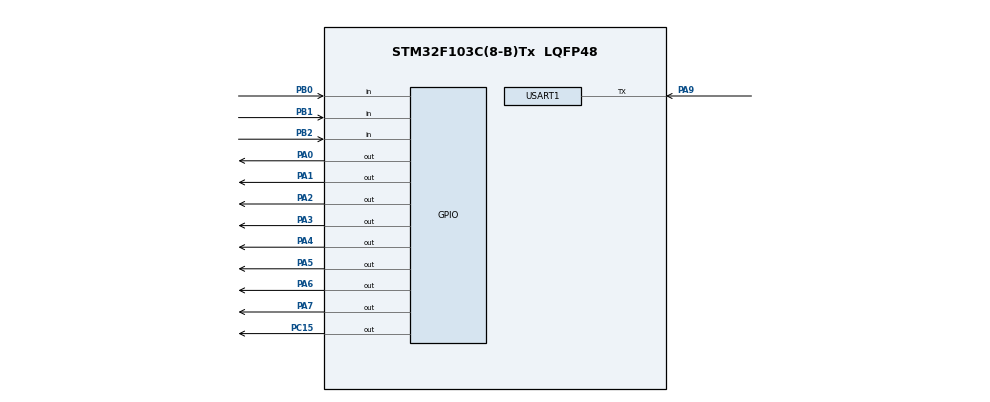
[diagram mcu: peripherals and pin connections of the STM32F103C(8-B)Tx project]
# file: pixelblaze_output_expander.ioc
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Dma.Request0=TIM1_CH1
Dma.Request1=TIM1_CH3
Dma.Request2=TIM1_CH4/TRIG/COM
Dma.Request3=USART1_RX
Dma.Request4=TIM2_CH2/CH4
Dma.TIM1_CH1.0.Direction=DMA_MEMORY_TO_PERIPH
Dma.TIM1_CH1.0.Instance=DMA1_Channel2
Dma.TIM1_CH1.0.MemDataAlignment=DMA_MDATAALIGN_BYTE
Dma.TIM1_CH1.0.MemInc=DMA_MINC_DISABLE
Dma.TIM1_CH1.0.Mode=DMA_CIRCULAR
Dma.TIM1_CH1.0.PeriphDataAlignment=DMA_PDATAALIGN_BYTE
Dma.TIM1_CH1.0.PeriphInc=DMA_PINC_DISABLE
Dma.TIM1_CH1.0.Priority=DMA_PRIORITY_VERY_HIGH
Dma.TIM1_CH3.1.Direction=DMA_MEMORY_TO_PERIPH
Dma.TIM1_CH3.1.Instance=DMA1_Channel6
Dma.TIM1_CH3.1.MemDataAlignment=DMA_MDATAALIGN_BYTE
Dma.TIM1_CH3.1.MemInc=DMA_MINC_ENABLE
Dma.TIM1_CH3.1.Mode=DMA_NORMAL
Dma.TIM1_CH3.1.PeriphDataAlignment=DMA_PDATAALIGN_BYTE
Dma.TIM1_CH3.1.PeriphInc=DMA_PINC_DISABLE
Dma.TIM1_CH3.1.Priority=DMA_PRIORITY_VERY_HIGH
Dma.TIM1_CH4/TRIG/COM.2.Direction=DMA_MEMORY_TO_PERIPH
Dma.TIM1_CH4/TRIG/COM.2.Instance=DMA1_Channel4
Dma.TIM1_CH4/TRIG/COM.2.MemDataAlignment=DMA_MDATAALIGN_BYTE
Dma.TIM1_CH4/TRIG/COM.2.MemInc=DMA_MINC_DISABLE
Dma.TIM1_CH4/TRIG/COM.2.Mode=DMA_CIRCULAR
Dma.TIM1_CH4/TRIG/COM.2.PeriphDataAlignment=DMA_PDATAALIGN_BYTE
Dma.TIM1_CH4/TRIG/COM.2.PeriphInc=DMA_PINC_DISABLE
Dma.TIM1_CH4/TRIG/COM.2.Priority=DMA_PRIORITY_VERY_HIGH
Dma.TIM2_CH2/CH4.4.Direction=DMA_MEMORY_TO_PERIPH
Dma.TIM2_CH2/CH4.4.Instance=DMA1_Channel7
Dma.TIM2_CH2/CH4.4.MemDataAlignment=DMA_MDATAALIGN_BYTE
Dma.TIM2_CH2/CH4.4.MemInc=DMA_MINC_DISABLE
Dma.TIM2_CH2/CH4.4.Mode=DMA_CIRCULAR
Dma.TIM2_CH2/CH4.4.PeriphDataAlignment=DMA_PDATAALIGN_BYTE
Dma.TIM2_CH2/CH4.4.PeriphInc=DMA_PINC_DISABLE
Dma.TIM2_CH2/CH4.4.Priority=DMA_PRIORITY_HIGH
Dma.USART1_RX.3.Direction=DMA_PERIPH_TO_MEMORY
Dma.USART1_RX.3.Instance=DMA1_Channel5
Dma.USART1_RX.3.MemDataAlignment=DMA_MDATAALIGN_BYTE
Dma.USART1_RX.3.MemInc=DMA_MINC_ENABLE
Dma.USART1_RX.3.Mode=DMA_CIRCULAR
Dma.USART1_RX.3.PeriphDataAlignment=DMA_PDATAALIGN_BYTE
Dma.USART1_RX.3.PeriphInc=DMA_PINC_DISABLE
Dma.USART1_RX.3.Priority=DMA_PRIORITY_LOW
Mcu.Family=STM32F1
Mcu.Name=STM32F103C(8-B)Tx
Mcu.Package=LQFP48
NVIC.DMA1_Channel2_IRQn=true\:0\:0\:false\:false\:true\:false\:true\:true
NVIC.DMA1_Channel4_IRQn=true\:0\:0\:false\:false\:true\:false\:true\:true
NVIC.DMA1_Channel5_IRQn=true\:0\:0\:false\:false\:true\:false\:true\:true
NVIC.DMA1_Channel6_IRQn=true\:0\:0\:false\:false\:true\:false\:true\:true
NVIC.DMA1_Channel7_IRQn=true\:0\:0\:false\:false\:true\:false\:true\:true
NVIC.PriorityGroup=NVIC_PRIORITYGROUP_4
NVIC.TIM4_IRQn=true\:0\:0\:false\:false\:true\:true\:true\:true
NVIC.USART1_IRQn=true\:0\:0\:false\:false\:true\:true\:true\:true
PA0-WKUP.Signal=GPIO_Output
PA1.Signal=GPIO_Output
PA13.Mode=Serial_Wire
PA13.Signal=SYS_JTMS-SWDIO
PA14.Mode=Serial_Wire
PA14.Signal=SYS_JTCK-SWCLK
PA2.Signal=GPIO_Output
PA3.Signal=GPIO_Output
PA4.Signal=GPIO_Output
PA5.Signal=GPIO_Output
PA6.Signal=GPIO_Output
PA7.Signal=GPIO_Output
PA9.Mode=Half_duplex(single_wire_mode)
PA9.Signal=USART1_TX
PB0.GPIO_PuPd=GPIO_PULLUP
PB0.Signal=GPIO_Input
PB1.GPIO_PuPd=GPIO_PULLUP
PB1.Signal=GPIO_Input
PB2.GPIO_PuPd=GPIO_PULLUP
PB2.Signal=GPIO_Input
PC15-OSC32_OUT.Signal=GPIO_Output
ProjectManager.HeapSize=0x0
ProjectManager.StackSize=0x0c0
ProjectManager.TargetToolchain=STM32CubeIDE
RCC.AHBFreq_Value=64000000
RCC.APB1CLKDivider=RCC_HCLK_DIV2
RCC.APB1Freq_Value=32000000
RCC.APB1TimFreq_Value=64000000
RCC.APB2Freq_Value=64000000
RCC.APB2TimFreq_Value=64000000
RCC.HCLKFreq_Value=64000000
RCC.PLLMUL=RCC_PLL_MUL16
RCC.SYSCLKFreq_VALUE=64000000
RCC.SYSCLKSource=RCC_SYSCLKSOURCE_PLLCLK
RCC.USBFreq_Value=64000000
TIM1.Channel-Output\ Compare1\ No\ Output=TIM_CHANNEL_1
TIM1.Channel-Output\ Compare3\ No\ Output=TIM_CHANNEL_3
TIM1.Channel-Output\ Compare4\ No\ Output=TIM_CHANNEL_4
TIM1.OCMode_1=TIM_OCMODE_ACTIVE
TIM1.OCMode_3=TIM_OCMODE_ACTIVE
TIM1.OCMode_4=TIM_OCMODE_ACTIVE
TIM1.Period=79
TIM1.Pulse-Output\ Compare1\ No\ Output=1
TIM1.Pulse-Output\ Compare3\ No\ Output=16
TIM1.Pulse-Output\ Compare4\ No\ Output=56
TIM2.Channel-Output\ Compare2\ No\ Output=TIM_CHANNEL_2
TIM2.OCMode_2=TIM_OCMODE_ACTIVE
TIM2.Period=79
TIM2.Pulse-Output\ Compare2\ No\ Output=64
TIM3.Channel-PWM\ Generation1\ No\ Output=TIM_CHANNEL_1
TIM3.OCMode_PWM-PWM\ Generation1\ No\ Output=TIM_OCMODE_PWM2
TIM3.Period=20159
TIM3.Prescaler=79
TIM3.Pulse-PWM\ Generation1\ No\ Output=1
TIM3.TIM_MasterOutputTrigger=TIM_TRGO_OC1REF
TIM3.TIM_MasterSlaveMode=TIM_MASTERSLAVEMODE_ENABLE
TIM4.ClockDivision=TIM_CLOCKDIVISION_DIV1
TIM4.Period=65535
TIM4.Prescaler=63
USART1.BaudRate=2000000
USART1.Mode=MODE_RX
USART1.VirtualMode=VM_ASYNC
VP_TIM1_VS_ClockSourceINT.Mode=Internal
VP_TIM1_VS_ClockSourceITR.Mode=TriggerSource_ITR2
VP_TIM1_VS_ControllerModeGated.Mode=Gated Mode
VP_TIM1_VS_no_output1.Mode=Output Compare1 No Output
VP_TIM1_VS_no_output3.Mode=Output Compare3 No Output
VP_TIM1_VS_no_output4.Mode=Output Compare4 No Output
VP_TIM2_VS_ClockSourceINT.Mode=Internal
VP_TIM2_VS_ClockSourceITR.Mode=TriggerSource_ITR2
VP_TIM2_VS_ControllerModeGated.Mode=Gated Mode
VP_TIM2_VS_no_output2.Mode=Output Compare2 No Output
VP_TIM3_VS_ClockSourceINT.Mode=Internal
VP_TIM3_VS_OPM.Mode=OPM_bit
VP_TIM3_VS_no_output1.Mode=PWM Generation1 No Output
VP_TIM4_VS_ClockSourceINT.Mode=Internal
VP_TIM4_VS_OPM.Mode=OPM_bit
board=custom

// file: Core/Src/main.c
/* USER CODE BEGIN Header */
/**
  ******************************************************************************
  * @file           : main.c
  * @brief          : Main program body
  ******************************************************************************
  * @attention
  *
  * <h2><center>&copy; Copyright (c) 2019 STMicroelectronics.
  * All rights reserved.</center></h2>
  *
  * This software component is licensed by ST under BSD 3-Clause license,
  * the "License"; You may not use this file except in compliance with the
  * License. You may obtain a copy of the License at:
  *                        opensource.org/licenses/BSD-3-Clause
  *
  ******************************************************************************
  */
/* USER CODE END Header */

#include "main.h"

/* USER CODE BEGIN Includes */

#include "app.h"

/* USER CODE END Includes */

void SystemClock_Config(void);
static void MX_GPIO_Init(void);
static void MX_USART1_UART_Init(void);
static void MX_DMA_Init(void);
static void MX_TIM1_Init(void);
static void MX_TIM3_Init(void);
static void MX_TIM4_Init(void);
static void MX_TIM2_Init(void);

int main(void)
{

  /* MCU Configuration--------------------------------------------------------*/

  /* Reset of all peripherals, Initializes the Flash interface and the Systick. */

  LL_APB2_GRP1_EnableClock(LL_APB2_GRP1_PERIPH_AFIO);
  LL_APB1_GRP1_EnableClock(LL_APB1_GRP1_PERIPH_PWR);

  NVIC_SetPriorityGrouping(NVIC_PRIORITYGROUP_4);

  /* System interrupt init*/

  /** NOJTAG: JTAG-DP Disabled and SW-DP Enabled
  */
  LL_GPIO_AF_Remap_SWJ_NOJTAG();

  /* Configure the system clock */
  SystemClock_Config();

  /* USER CODE BEGIN SysInit */

  MX_GPIO_Init();
  MX_DMA_Init(); //dma before uart, or uart dma init code fails
  MX_USART1_UART_Init();
  MX_TIM1_Init();
  MX_TIM3_Init();
  MX_TIM4_Init();
  MX_TIM2_Init();

#if 0

  /* USER CODE END SysInit */

  /* Initialize all configured peripherals */
  MX_GPIO_Init();
  MX_USART1_UART_Init();
  MX_DMA_Init();
  MX_TIM1_Init();
  MX_TIM3_Init();
  MX_TIM4_Init();
  MX_TIM2_Init();
  /* USER CODE BEGIN 2 */

#endif

  setup();

  /* USER CODE END 2 */

  /* Infinite loop */
  while (1)
  {

    /* USER CODE BEGIN 3 */
	  loop();
  }
  /* USER CODE END 3 */
}

void SystemClock_Config(void)
{
  LL_FLASH_SetLatency(LL_FLASH_LATENCY_2);

   if(LL_FLASH_GetLatency() != LL_FLASH_LATENCY_2)
  {
    Error_Handler();
  }
  LL_RCC_HSI_SetCalibTrimming(16);
  LL_RCC_HSI_Enable();

   /* Wait till HSI is ready */
  while(LL_RCC_HSI_IsReady() != 1)
  {

  }
  LL_RCC_PLL_ConfigDomain_SYS(LL_RCC_PLLSOURCE_HSI_DIV_2, LL_RCC_PLL_MUL_16);
  LL_RCC_PLL_Enable();

   /* Wait till PLL is ready */
  while(LL_RCC_PLL_IsReady() != 1)
  {

  }
  LL_RCC_SetAHBPrescaler(LL_RCC_SYSCLK_DIV_1);
  LL_RCC_SetAPB1Prescaler(LL_RCC_APB1_DIV_2);
  LL_RCC_SetAPB2Prescaler(LL_RCC_APB2_DIV_1);
  LL_RCC_SetSysClkSource(LL_RCC_SYS_CLKSOURCE_PLL);

   /* Wait till System clock is ready */
  while(LL_RCC_GetSysClkSource() != LL_RCC_SYS_CLKSOURCE_STATUS_PLL)
  {

  }
  LL_Init1msTick(64000000);
  LL_SYSTICK_SetClkSource(LL_SYSTICK_CLKSOURCE_HCLK);
  LL_SetSystemCoreClock(64000000);
}

static void MX_TIM1_Init(void)
{

  LL_TIM_InitTypeDef TIM_InitStruct = {0};
  LL_TIM_OC_InitTypeDef TIM_OC_InitStruct = {0};
  LL_TIM_BDTR_InitTypeDef TIM_BDTRInitStruct = {0};

  /* Peripheral clock enable */
  LL_APB2_GRP1_EnableClock(LL_APB2_GRP1_PERIPH_TIM1);

  /* TIM1 DMA Init */

  /* TIM1_CH1 Init */
  LL_DMA_SetDataTransferDirection(DMA1, LL_DMA_CHANNEL_2, LL_DMA_DIRECTION_MEMORY_TO_PERIPH);

  LL_DMA_SetChannelPriorityLevel(DMA1, LL_DMA_CHANNEL_2, LL_DMA_PRIORITY_VERYHIGH);

  LL_DMA_SetMode(DMA1, LL_DMA_CHANNEL_2, LL_DMA_MODE_CIRCULAR);

  LL_DMA_SetPeriphIncMode(DMA1, LL_DMA_CHANNEL_2, LL_DMA_PERIPH_NOINCREMENT);

  LL_DMA_SetMemoryIncMode(DMA1, LL_DMA_CHANNEL_2, LL_DMA_MEMORY_NOINCREMENT);

  LL_DMA_SetPeriphSize(DMA1, LL_DMA_CHANNEL_2, LL_DMA_PDATAALIGN_BYTE);

  LL_DMA_SetMemorySize(DMA1, LL_DMA_CHANNEL_2, LL_DMA_MDATAALIGN_BYTE);

  /* TIM1_CH3 Init */
  LL_DMA_SetDataTransferDirection(DMA1, LL_DMA_CHANNEL_6, LL_DMA_DIRECTION_MEMORY_TO_PERIPH);

  LL_DMA_SetChannelPriorityLevel(DMA1, LL_DMA_CHANNEL_6, LL_DMA_PRIORITY_VERYHIGH);

  LL_DMA_SetMode(DMA1, LL_DMA_CHANNEL_6, LL_DMA_MODE_NORMAL);

  LL_DMA_SetPeriphIncMode(DMA1, LL_DMA_CHANNEL_6, LL_DMA_PERIPH_NOINCREMENT);

  LL_DMA_SetMemoryIncMode(DMA1, LL_DMA_CHANNEL_6, LL_DMA_MEMORY_INCREMENT);

  LL_DMA_SetPeriphSize(DMA1, LL_DMA_CHANNEL_6, LL_DMA_PDATAALIGN_BYTE);

  LL_DMA_SetMemorySize(DMA1, LL_DMA_CHANNEL_6, LL_DMA_MDATAALIGN_BYTE);

  /* TIM1_CH4_TRIG_COM Init */
  LL_DMA_SetDataTransferDirection(DMA1, LL_DMA_CHANNEL_4, LL_DMA_DIRECTION_MEMORY_TO_PERIPH);

  LL_DMA_SetChannelPriorityLevel(DMA1, LL_DMA_CHANNEL_4, LL_DMA_PRIORITY_VERYHIGH);

  LL_DMA_SetMode(DMA1, LL_DMA_CHANNEL_4, LL_DMA_MODE_CIRCULAR);

  LL_DMA_SetPeriphIncMode(DMA1, LL_DMA_CHANNEL_4, LL_DMA_PERIPH_NOINCREMENT);

  LL_DMA_SetMemoryIncMode(DMA1, LL_DMA_CHANNEL_4, LL_DMA_MEMORY_NOINCREMENT);

  LL_DMA_SetPeriphSize(DMA1, LL_DMA_CHANNEL_4, LL_DMA_PDATAALIGN_BYTE);

  LL_DMA_SetMemorySize(DMA1, LL_DMA_CHANNEL_4, LL_DMA_MDATAALIGN_BYTE);

  TIM_InitStruct.Prescaler = 0;
  TIM_InitStruct.CounterMode = LL_TIM_COUNTERMODE_UP;
  TIM_InitStruct.Autoreload = TIM1_CYCLE_COUNT;
  TIM_InitStruct.ClockDivision = LL_TIM_CLOCKDIVISION_DIV1;
  TIM_InitStruct.RepetitionCounter = 0;
  LL_TIM_Init(TIM1, &TIM_InitStruct);
  LL_TIM_DisableARRPreload(TIM1);
  LL_TIM_SetClockSource(TIM1, LL_TIM_CLOCKSOURCE_INTERNAL);
  TIM_OC_InitStruct.OCMode = LL_TIM_OCMODE_ACTIVE;
  TIM_OC_InitStruct.OCState = LL_TIM_OCSTATE_DISABLE;
  TIM_OC_InitStruct.OCNState = LL_TIM_OCSTATE_DISABLE;
  TIM_OC_InitStruct.CompareValue = TIM1_COMPARE_CH1;
  TIM_OC_InitStruct.OCPolarity = LL_TIM_OCPOLARITY_HIGH;
  TIM_OC_InitStruct.OCNPolarity = LL_TIM_OCPOLARITY_HIGH;
  TIM_OC_InitStruct.OCIdleState = LL_TIM_OCIDLESTATE_LOW;
  TIM_OC_InitStruct.OCNIdleState = LL_TIM_OCIDLESTATE_LOW;
  LL_TIM_OC_Init(TIM1, LL_TIM_CHANNEL_CH1, &TIM_OC_InitStruct);
  LL_TIM_OC_DisableFast(TIM1, LL_TIM_CHANNEL_CH1);
  TIM_OC_InitStruct.OCState = LL_TIM_OCSTATE_DISABLE;
  TIM_OC_InitStruct.OCNState = LL_TIM_OCSTATE_DISABLE;
  TIM_OC_InitStruct.CompareValue = TIM1_COMPARE_CH3;
  LL_TIM_OC_Init(TIM1, LL_TIM_CHANNEL_CH3, &TIM_OC_InitStruct);
  LL_TIM_OC_DisableFast(TIM1, LL_TIM_CHANNEL_CH3);
  TIM_OC_InitStruct.OCState = LL_TIM_OCSTATE_DISABLE;
  TIM_OC_InitStruct.OCNState = LL_TIM_OCSTATE_DISABLE;
  TIM_OC_InitStruct.CompareValue = TIM1_COMPARE_CH4;
  LL_TIM_OC_Init(TIM1, LL_TIM_CHANNEL_CH4, &TIM_OC_InitStruct);
  LL_TIM_OC_DisableFast(TIM1, LL_TIM_CHANNEL_CH4);
  LL_TIM_SetTriggerInput(TIM1, LL_TIM_TS_ITR2);
  LL_TIM_SetSlaveMode(TIM1, LL_TIM_SLAVEMODE_GATED);
  LL_TIM_DisableIT_TRIG(TIM1);
  LL_TIM_DisableDMAReq_TRIG(TIM1);
  LL_TIM_SetTriggerOutput(TIM1, LL_TIM_TRGO_RESET);
  LL_TIM_DisableMasterSlaveMode(TIM1);
  TIM_BDTRInitStruct.OSSRState = LL_TIM_OSSR_DISABLE;
  TIM_BDTRInitStruct.OSSIState = LL_TIM_OSSI_DISABLE;
  TIM_BDTRInitStruct.LockLevel = LL_TIM_LOCKLEVEL_OFF;
  TIM_BDTRInitStruct.DeadTime = 0;
  TIM_BDTRInitStruct.BreakState = LL_TIM_BREAK_DISABLE;
  TIM_BDTRInitStruct.BreakPolarity = LL_TIM_BREAK_POLARITY_HIGH;
  TIM_BDTRInitStruct.AutomaticOutput = LL_TIM_AUTOMATICOUTPUT_DISABLE;
  LL_TIM_BDTR_Init(TIM1, &TIM_BDTRInitStruct);

}

static void MX_TIM2_Init(void)
{

  LL_TIM_InitTypeDef TIM_InitStruct = {0};
  LL_TIM_OC_InitTypeDef TIM_OC_InitStruct = {0};

  /* Peripheral clock enable */
  LL_APB1_GRP1_EnableClock(LL_APB1_GRP1_PERIPH_TIM2);

  /* TIM2 DMA Init */

  /* TIM2_CH2_CH4 Init */
  LL_DMA_SetDataTransferDirection(DMA1, LL_DMA_CHANNEL_7, LL_DMA_DIRECTION_MEMORY_TO_PERIPH);

  LL_DMA_SetChannelPriorityLevel(DMA1, LL_DMA_CHANNEL_7, LL_DMA_PRIORITY_HIGH);

  LL_DMA_SetMode(DMA1, LL_DMA_CHANNEL_7, LL_DMA_MODE_CIRCULAR);

  LL_DMA_SetPeriphIncMode(DMA1, LL_DMA_CHANNEL_7, LL_DMA_PERIPH_NOINCREMENT);

  LL_DMA_SetMemoryIncMode(DMA1, LL_DMA_CHANNEL_7, LL_DMA_MEMORY_NOINCREMENT);

  LL_DMA_SetPeriphSize(DMA1, LL_DMA_CHANNEL_7, LL_DMA_PDATAALIGN_BYTE);

  LL_DMA_SetMemorySize(DMA1, LL_DMA_CHANNEL_7, LL_DMA_MDATAALIGN_BYTE);

  TIM_InitStruct.Prescaler = 0;
  TIM_InitStruct.CounterMode = LL_TIM_COUNTERMODE_UP;
  TIM_InitStruct.Autoreload = TIM1_CYCLE_COUNT;
  TIM_InitStruct.ClockDivision = LL_TIM_CLOCKDIVISION_DIV1;
  LL_TIM_Init(TIM2, &TIM_InitStruct);
  LL_TIM_DisableARRPreload(TIM2);
  LL_TIM_SetClockSource(TIM2, LL_TIM_CLOCKSOURCE_INTERNAL);
  TIM_OC_InitStruct.OCMode = LL_TIM_OCMODE_ACTIVE;
  TIM_OC_InitStruct.OCState = LL_TIM_OCSTATE_DISABLE;
  TIM_OC_InitStruct.OCNState = LL_TIM_OCSTATE_DISABLE;
  TIM_OC_InitStruct.CompareValue = TIM2_COMPARE_CH2;
  TIM_OC_InitStruct.OCPolarity = LL_TIM_OCPOLARITY_HIGH;
  LL_TIM_OC_Init(TIM2, LL_TIM_CHANNEL_CH2, &TIM_OC_InitStruct);
  LL_TIM_OC_DisableFast(TIM2, LL_TIM_CHANNEL_CH2);
  LL_TIM_SetTriggerInput(TIM2, LL_TIM_TS_ITR2);
  LL_TIM_SetSlaveMode(TIM2, LL_TIM_SLAVEMODE_GATED);
  LL_TIM_DisableIT_TRIG(TIM2);
  LL_TIM_DisableDMAReq_TRIG(TIM2);
  LL_TIM_SetTriggerOutput(TIM2, LL_TIM_TRGO_RESET);
  LL_TIM_DisableMasterSlaveMode(TIM2);

}

static void MX_TIM3_Init(void)
{

  LL_TIM_InitTypeDef TIM_InitStruct = {0};
  LL_TIM_OC_InitTypeDef TIM_OC_InitStruct = {0};

  /* Peripheral clock enable */
  LL_APB1_GRP1_EnableClock(LL_APB1_GRP1_PERIPH_TIM3);

  TIM_InitStruct.Prescaler = TIM1_CYCLE_COUNT;
  TIM_InitStruct.CounterMode = LL_TIM_COUNTERMODE_UP;
  TIM_InitStruct.Autoreload = 20159;
  TIM_InitStruct.ClockDivision = LL_TIM_CLOCKDIVISION_DIV1;
  LL_TIM_Init(TIM3, &TIM_InitStruct);
  LL_TIM_DisableARRPreload(TIM3);
  LL_TIM_SetClockSource(TIM3, LL_TIM_CLOCKSOURCE_INTERNAL);
  LL_TIM_OC_EnablePreload(TIM3, LL_TIM_CHANNEL_CH1);
  TIM_OC_InitStruct.OCMode = LL_TIM_OCMODE_PWM2;
  TIM_OC_InitStruct.OCState = LL_TIM_OCSTATE_DISABLE;
  TIM_OC_InitStruct.OCNState = LL_TIM_OCSTATE_DISABLE;
  TIM_OC_InitStruct.CompareValue = 1;
  TIM_OC_InitStruct.OCPolarity = LL_TIM_OCPOLARITY_HIGH;
  LL_TIM_OC_Init(TIM3, LL_TIM_CHANNEL_CH1, &TIM_OC_InitStruct);
  LL_TIM_OC_DisableFast(TIM3, LL_TIM_CHANNEL_CH1);
  LL_TIM_SetOnePulseMode(TIM3, LL_TIM_ONEPULSEMODE_SINGLE);
  LL_TIM_SetTriggerOutput(TIM3, LL_TIM_TRGO_OC1REF);
  LL_TIM_EnableMasterSlaveMode(TIM3);

}

static void MX_TIM4_Init(void)
{

  LL_TIM_InitTypeDef TIM_InitStruct = {0};

  /* Peripheral clock enable */
  LL_APB1_GRP1_EnableClock(LL_APB1_GRP1_PERIPH_TIM4);

  /* TIM4 interrupt Init */
  NVIC_SetPriority(TIM4_IRQn, NVIC_EncodePriority(NVIC_GetPriorityGrouping(),0, 0));
  NVIC_EnableIRQ(TIM4_IRQn);

  TIM_InitStruct.Prescaler = 63;
  TIM_InitStruct.CounterMode = LL_TIM_COUNTERMODE_UP;
  TIM_InitStruct.Autoreload = 65535;
  TIM_InitStruct.ClockDivision = LL_TIM_CLOCKDIVISION_DIV1;
  LL_TIM_Init(TIM4, &TIM_InitStruct);
  LL_TIM_DisableARRPreload(TIM4);
  LL_TIM_SetClockSource(TIM4, LL_TIM_CLOCKSOURCE_INTERNAL);
  LL_TIM_SetOnePulseMode(TIM4, LL_TIM_ONEPULSEMODE_SINGLE);
  LL_TIM_SetTriggerOutput(TIM4, LL_TIM_TRGO_RESET);
  LL_TIM_DisableMasterSlaveMode(TIM4);

}

static void MX_USART1_UART_Init(void)
{

  LL_USART_InitTypeDef USART_InitStruct = {0};

  LL_GPIO_InitTypeDef GPIO_InitStruct = {0};

  /* Peripheral clock enable */
  LL_APB2_GRP1_EnableClock(LL_APB2_GRP1_PERIPH_USART1);

  LL_APB2_GRP1_EnableClock(LL_APB2_GRP1_PERIPH_GPIOA);
  /**USART1 GPIO Configuration
  PA9   ------> USART1_TX
  */
  GPIO_InitStruct.Pin = LL_GPIO_PIN_9;
  GPIO_InitStruct.Mode = LL_GPIO_MODE_ALTERNATE;
  GPIO_InitStruct.Speed = LL_GPIO_SPEED_FREQ_HIGH;
  GPIO_InitStruct.OutputType = LL_GPIO_OUTPUT_OPENDRAIN;
  LL_GPIO_Init(GPIOA, &GPIO_InitStruct);

  /* USART1 DMA Init */

  /* USART1_RX Init */
  LL_DMA_SetDataTransferDirection(DMA1, LL_DMA_CHANNEL_5, LL_DMA_DIRECTION_PERIPH_TO_MEMORY);

  LL_DMA_SetChannelPriorityLevel(DMA1, LL_DMA_CHANNEL_5, LL_DMA_PRIORITY_LOW);

  LL_DMA_SetMode(DMA1, LL_DMA_CHANNEL_5, LL_DMA_MODE_CIRCULAR);

  LL_DMA_SetPeriphIncMode(DMA1, LL_DMA_CHANNEL_5, LL_DMA_PERIPH_NOINCREMENT);

  LL_DMA_SetMemoryIncMode(DMA1, LL_DMA_CHANNEL_5, LL_DMA_MEMORY_INCREMENT);

  LL_DMA_SetPeriphSize(DMA1, LL_DMA_CHANNEL_5, LL_DMA_PDATAALIGN_BYTE);

  LL_DMA_SetMemorySize(DMA1, LL_DMA_CHANNEL_5, LL_DMA_MDATAALIGN_BYTE);

  /* USART1 interrupt Init */
  NVIC_SetPriority(USART1_IRQn, NVIC_EncodePriority(NVIC_GetPriorityGrouping(),0, 0));
  NVIC_EnableIRQ(USART1_IRQn);

  USART_InitStruct.BaudRate = 2000000;
  USART_InitStruct.DataWidth = LL_USART_DATAWIDTH_8B;
  USART_InitStruct.StopBits = LL_USART_STOPBITS_1;
  USART_InitStruct.Parity = LL_USART_PARITY_NONE;
  USART_InitStruct.TransferDirection = LL_USART_DIRECTION_RX;
  USART_InitStruct.OverSampling = LL_USART_OVERSAMPLING_16;
  LL_USART_Init(USART1, &USART_InitStruct);
  LL_USART_ConfigHalfDuplexMode(USART1);
  LL_USART_Enable(USART1);

}

static void MX_DMA_Init(void)
{

  /* Init with LL driver */
  /* DMA controller clock enable */
  LL_AHB1_GRP1_EnableClock(LL_AHB1_GRP1_PERIPH_DMA1);

  /* DMA interrupt init */
  /* DMA1_Channel2_IRQn interrupt configuration */
  NVIC_SetPriority(DMA1_Channel2_IRQn, NVIC_EncodePriority(NVIC_GetPriorityGrouping(),0, 0));
  NVIC_EnableIRQ(DMA1_Channel2_IRQn);
  /* DMA1_Channel4_IRQn interrupt configuration */
  NVIC_SetPriority(DMA1_Channel4_IRQn, NVIC_EncodePriority(NVIC_GetPriorityGrouping(),0, 0));
  NVIC_EnableIRQ(DMA1_Channel4_IRQn);
  /* DMA1_Channel5_IRQn interrupt configuration */
  NVIC_SetPriority(DMA1_Channel5_IRQn, NVIC_EncodePriority(NVIC_GetPriorityGrouping(),0, 0));
  NVIC_EnableIRQ(DMA1_Channel5_IRQn);
  /* DMA1_Channel6_IRQn interrupt configuration */
  NVIC_SetPriority(DMA1_Channel6_IRQn, NVIC_EncodePriority(NVIC_GetPriorityGrouping(),0, 0));
  NVIC_EnableIRQ(DMA1_Channel6_IRQn);
  /* DMA1_Channel7_IRQn interrupt configuration */
  NVIC_SetPriority(DMA1_Channel7_IRQn, NVIC_EncodePriority(NVIC_GetPriorityGrouping(),0, 0));
  NVIC_EnableIRQ(DMA1_Channel7_IRQn);

}

static void MX_GPIO_Init(void)
{
  LL_GPIO_InitTypeDef GPIO_InitStruct = {0};

  /* GPIO Ports Clock Enable */
  LL_APB2_GRP1_EnableClock(LL_APB2_GRP1_PERIPH_GPIOC);
  LL_APB2_GRP1_EnableClock(LL_APB2_GRP1_PERIPH_GPIOA);
  LL_APB2_GRP1_EnableClock(LL_APB2_GRP1_PERIPH_GPIOB);

  /**/
  LL_GPIO_ResetOutputPin(GPIOC, LL_GPIO_PIN_15);

  /**/
  LL_GPIO_ResetOutputPin(GPIOA, LL_GPIO_PIN_0|LL_GPIO_PIN_1|LL_GPIO_PIN_2|LL_GPIO_PIN_3
                          |LL_GPIO_PIN_4|LL_GPIO_PIN_5|LL_GPIO_PIN_6|LL_GPIO_PIN_7);

  /**/
  GPIO_InitStruct.Pin = LL_GPIO_PIN_15;
  GPIO_InitStruct.Mode = LL_GPIO_MODE_OUTPUT;
  GPIO_InitStruct.Speed = LL_GPIO_SPEED_FREQ_LOW;
  GPIO_InitStruct.OutputType = LL_GPIO_OUTPUT_PUSHPULL;
  LL_GPIO_Init(GPIOC, &GPIO_InitStruct);

  /**/
  GPIO_InitStruct.Pin = LL_GPIO_PIN_0|LL_GPIO_PIN_1|LL_GPIO_PIN_2|LL_GPIO_PIN_3
                          |LL_GPIO_PIN_4|LL_GPIO_PIN_5|LL_GPIO_PIN_6|LL_GPIO_PIN_7;
  GPIO_InitStruct.Mode = LL_GPIO_MODE_OUTPUT;
  GPIO_InitStruct.Speed = LL_GPIO_SPEED_FREQ_LOW;
  GPIO_InitStruct.OutputType = LL_GPIO_OUTPUT_PUSHPULL;
  LL_GPIO_Init(GPIOA, &GPIO_InitStruct);

  /**/
  GPIO_InitStruct.Pin = LL_GPIO_PIN_0|LL_GPIO_PIN_1|LL_GPIO_PIN_2;
  GPIO_InitStruct.Mode = LL_GPIO_MODE_INPUT;
  GPIO_InitStruct.Pull = LL_GPIO_PULL_UP;
  LL_GPIO_Init(GPIOB, &GPIO_InitStruct);

}

void Error_Handler(void)
{
}

/************************ (C) COPYRIGHT STMicroelectronics *****END OF FILE****/
